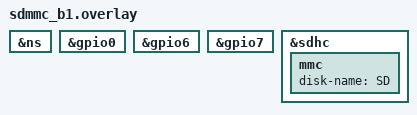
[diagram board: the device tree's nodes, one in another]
/* Copyright Alif Semiconductor - All Rights Reserved.
 * Use, distribution and modification of this code is permitted under the
 * terms stated in the Alif Semiconductor Software License Agreement
 *
 * You should have received a copy of the Alif Semiconductor Software
 * License Agreement with this file. If not, please write to:
 * contact@alifsemi.com, or visit: https://alifsemi.com/license
 */

ns: &ns {
	status = "okay";
};

/* GPIO0 is needed for SDHC sd-vsel regulator */
&gpio0 {
	status = "okay";
};

/* GPIO6 is needed for SDHC card-detect */
&gpio6 {
	status = "okay";
};

/* GPIO7 is needed for SDHC sd-pwr regulator */
&gpio7 {
	status = "okay";
};

sdhc: &sdhc {
	status = "okay";

	mmc {
		status = "okay";
		disk-name = "SD";
	};
};
